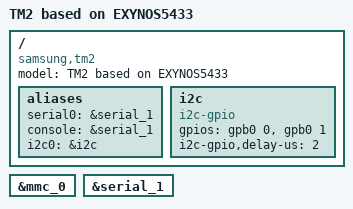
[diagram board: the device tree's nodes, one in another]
/*
 * TM2 device tree source
 *
 * Copyright (c) 2018 Samsung Electronics Co., Ltd.
 *		http://www.samsung.com
 *
 * SPDX-License-Identifier:	GPL-2.0+
 */

/dts-v1/;
#include "exynos5433.dtsi"

/ {
	model = "TM2 based on EXYNOS5433";
	compatible = "samsung,tm2", "samsung,exynos5433";

	aliases {
		serial0 = &serial_1;
		console = &serial_1;
		i2c0 = &i2c;
	};

	i2c: i2c {
		compatible = "i2c-gpio";
		gpios = <&gpb0 0 0>,	/* sda */
			<&gpb0 1 0>;	/* scl */
		i2c-gpio,delay-us = <2>;        /* ~100 kHz */
	};
};

&mmc_0 {
	status = "okay";
};

&serial_1 {
	status = "okay";
};
